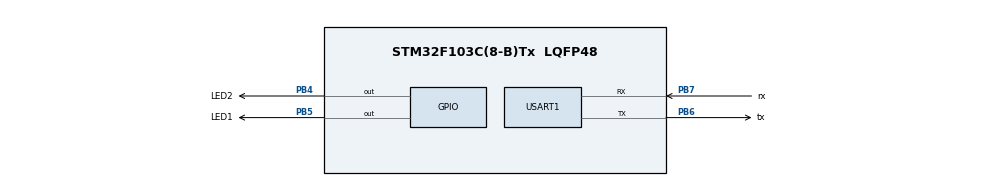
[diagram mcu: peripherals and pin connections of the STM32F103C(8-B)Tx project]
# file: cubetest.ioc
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Mcu.Family=STM32F1
Mcu.Name=STM32F103C(8-B)Tx
Mcu.Package=LQFP48
NVIC.PriorityGroup=NVIC_PRIORITYGROUP_4
PB4.GPIO_Label=LED2
PB4.Signal=GPIO_Output
PB5.GPIO_Label=LED1
PB5.Signal=GPIO_Output
PB6.GPIO_Label=tx
PB6.Mode=Asynchronous
PB6.Signal=USART1_TX
PB7.GPIO_Label=rx
PB7.Mode=Asynchronous
PB7.Signal=USART1_RX
PD0-OSC_IN.Mode=HSE-External-Oscillator
PD0-OSC_IN.Signal=RCC_OSC_IN
PD1-OSC_OUT.Mode=HSE-External-Oscillator
PD1-OSC_OUT.Signal=RCC_OSC_OUT
ProjectManager.HeapSize=0x200
ProjectManager.StackSize=0x400
ProjectManager.TargetToolchain=MDK-ARM V5
RCC.AHBFreq_Value=8000000
RCC.APB1Freq_Value=8000000
RCC.APB1TimFreq_Value=8000000
RCC.APB2Freq_Value=8000000
RCC.APB2TimFreq_Value=8000000
RCC.HCLKFreq_Value=8000000
USART1.VirtualMode=VM_ASYNC
VP_SYS_VS_ND.Mode=No_Debug
board=custom

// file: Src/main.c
/* USER CODE BEGIN Header */
/**
  ******************************************************************************
  * @file           : main.c
  * @brief          : Main program body
  ******************************************************************************
  ** This notice applies to any and all portions of this file
  * that are not between comment pairs USER CODE BEGIN and
  * USER CODE END. Other portions of this file, whether
  * inserted by the user or by software development tools
  * are owned by their respective copyright owners.
  *
  * COPYRIGHT(c) 2019 STMicroelectronics
  *
  * Redistribution and use in source and binary forms, with or without modification,
  * are permitted provided that the following conditions are met:
  *   1. Redistributions of source code must retain the above copyright notice,
  *      this list of conditions and the following disclaimer.
  *   2. Redistributions in binary form must reproduce the above copyright notice,
  *      this list of conditions and the following disclaimer in the documentation
  *      and/or other materials provided with the distribution.
  *   3. Neither the name of STMicroelectronics nor the names of its contributors
  *      may be used to endorse or promote products derived from this software
  *      without specific prior written permission.
  *
  * THIS SOFTWARE IS PROVIDED BY THE COPYRIGHT HOLDERS AND CONTRIBUTORS "AS IS"
  * AND ANY EXPRESS OR IMPLIED WARRANTIES, INCLUDING, BUT NOT LIMITED TO, THE
  * IMPLIED WARRANTIES OF MERCHANTABILITY AND FITNESS FOR A PARTICULAR PURPOSE ARE
  * DISCLAIMED. IN NO EVENT SHALL THE COPYRIGHT HOLDER OR CONTRIBUTORS BE LIABLE
  * FOR ANY DIRECT, INDIRECT, INCIDENTAL, SPECIAL, EXEMPLARY, OR CONSEQUENTIAL
  * DAMAGES (INCLUDING, BUT NOT LIMITED TO, PROCUREMENT OF SUBSTITUTE GOODS OR
  * SERVICES; LOSS OF USE, DATA, OR PROFITS; OR BUSINESS INTERRUPTION) HOWEVER
  * CAUSED AND ON ANY THEORY OF LIABILITY, WHETHER IN CONTRACT, STRICT LIABILITY,
  * OR TORT (INCLUDING NEGLIGENCE OR OTHERWISE) ARISING IN ANY WAY OUT OF THE USE
  * OF THIS SOFTWARE, EVEN IF ADVISED OF THE POSSIBILITY OF SUCH DAMAGE.
  *
  ******************************************************************************
  */
/* USER CODE END Header */

#include "main.h"
#include "usart.h"
#include "gpio.h"

void SystemClock_Config(void);

int main(void)
{

  /* MCU Configuration--------------------------------------------------------*/

  /* Reset of all peripherals, Initializes the Flash interface and the Systick. */
  HAL_Init();

  /* Configure the system clock */
  SystemClock_Config();

  /* Initialize all configured peripherals */
  MX_GPIO_Init();
  MX_USART1_UART_Init();

  /* Infinite loop */
  while (1)
  {

    /* USER CODE BEGIN 3 */
		HAL_Delay(1000);
		HAL_GPIO_WritePin(LED1_GPIO_Port,LED1_Pin,GPIO_PIN_SET);
		HAL_Delay(1000);
		HAL_GPIO_WritePin(LED1_GPIO_Port,LED1_Pin,GPIO_PIN_RESET);
  }
  /* USER CODE END 3 */
}

void SystemClock_Config(void)
{
  RCC_OscInitTypeDef RCC_OscInitStruct = {0};
  RCC_ClkInitTypeDef RCC_ClkInitStruct = {0};

  /**Initializes the CPU, AHB and APB busses clocks
  */
  RCC_OscInitStruct.OscillatorType = RCC_OSCILLATORTYPE_HSI;
  RCC_OscInitStruct.HSIState = RCC_HSI_ON;
  RCC_OscInitStruct.HSICalibrationValue = RCC_HSICALIBRATION_DEFAULT;
  RCC_OscInitStruct.PLL.PLLState = RCC_PLL_NONE;
  if (HAL_RCC_OscConfig(&RCC_OscInitStruct) != HAL_OK)
  {
    Error_Handler();
  }
  /**Initializes the CPU, AHB and APB busses clocks
  */
  RCC_ClkInitStruct.ClockType = RCC_CLOCKTYPE_HCLK|RCC_CLOCKTYPE_SYSCLK
                              |RCC_CLOCKTYPE_PCLK1|RCC_CLOCKTYPE_PCLK2;
  RCC_ClkInitStruct.SYSCLKSource = RCC_SYSCLKSOURCE_HSI;
  RCC_ClkInitStruct.AHBCLKDivider = RCC_SYSCLK_DIV1;
  RCC_ClkInitStruct.APB1CLKDivider = RCC_HCLK_DIV1;
  RCC_ClkInitStruct.APB2CLKDivider = RCC_HCLK_DIV1;

  if (HAL_RCC_ClockConfig(&RCC_ClkInitStruct, FLASH_LATENCY_0) != HAL_OK)
  {
    Error_Handler();
  }
}

/* USER CODE BEGIN 4 */
void test()
{
	test();
}

/* USER CODE END 4 */

void Error_Handler(void)
{
}

/************************ (C) COPYRIGHT STMicroelectronics *****END OF FILE****/
